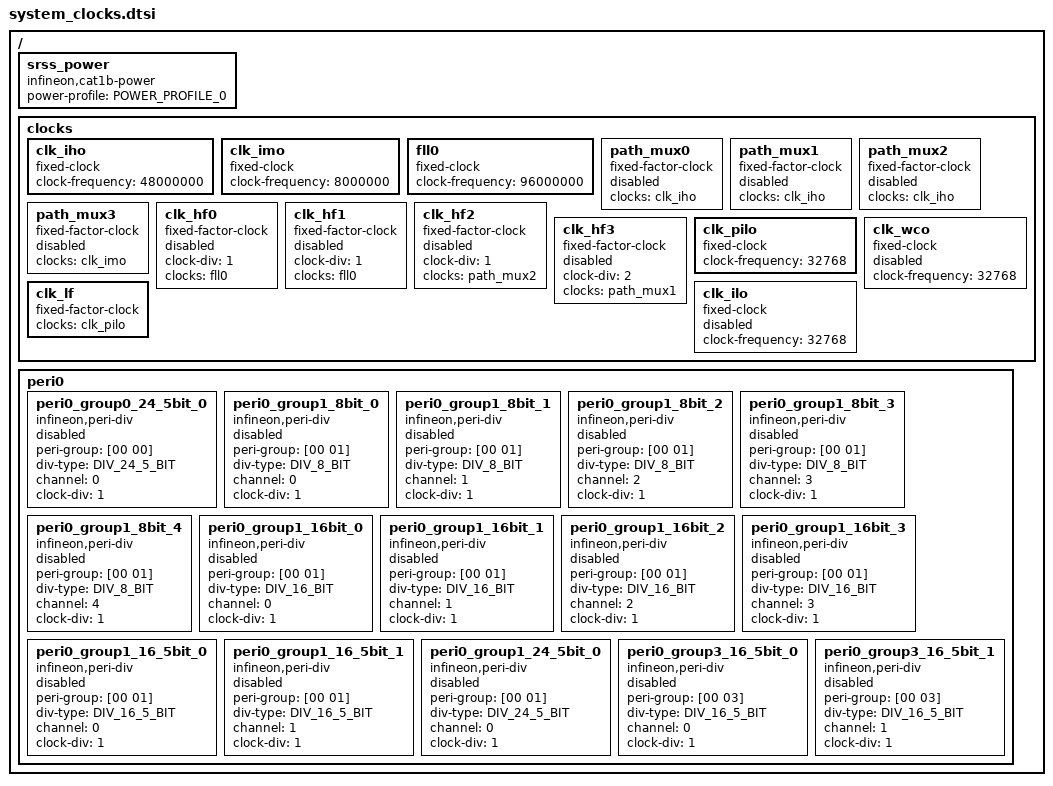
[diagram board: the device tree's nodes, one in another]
/*
 * Copyright (c) 2024 Cypress Semiconductor Corporation (an Infineon company) or
 * an affiliate of Cypress Semiconductor Corporation
 *
 * SPDX-License-Identifier: Apache-2.0
 */

#define DIV_8_BIT    00
#define DIV_16_BIT	 01
#define DIV_16_5_BIT 02
#define DIV_24_5_BIT 03

#include <dt-bindings/clock/ifx_clock_source_common.h>

/ {
	srss_power: srss_power {
		#clock-cells = <0>;
		compatible = "infineon,cat1b-power";
		power-profile = "POWER_PROFILE_0";
		status = "okay";
	};

	clocks {
		/* iho */
		clk_iho: clk_iho {
			#clock-cells = <0>;
			compatible = "fixed-clock";
			clock-frequency = <48000000>;
			status = "okay";
		};

		/* imo */
		clk_imo: clk_imo {
			#clock-cells = <0>;
			compatible = "fixed-clock";
			clock-frequency = <8000000>;
			status = "okay";
		};

		/* fll */
		fll0: fll0 {
			#clock-cells = <0>;
			compatible = "fixed-clock";
			clock-frequency = <96000000>;
			status = "okay";
		};

		/* path mux0 */
		path_mux0: path_mux0 {
			#clock-cells = <0>;
			compatible = "fixed-factor-clock";
			clocks = <&clk_iho>;
			status = "disabled";
		};

		/* path mux1 */
		path_mux1: path_mux1 {
			#clock-cells = <0>;
			compatible = "fixed-factor-clock";
			clocks = <&clk_iho>;
			status = "disabled";
		};

		/* path mux2 */
		path_mux2: path_mux2 {
			#clock-cells = <0>;
			compatible = "fixed-factor-clock";
			clocks = <&clk_iho>;
			status = "disabled";
		};

		/* path mux3 */
		path_mux3: path_mux3 {
			#clock-cells = <0>;
			compatible = "fixed-factor-clock";
			clocks = <&clk_imo>;
			status = "disabled";
		};

		/* clk_hf0 */
		clk_hf0: clk_hf0 {
			#clock-cells = <0>;
			compatible = "fixed-factor-clock";
			clock-div = <1>;
			clocks = <&fll0>;
			status = "disabled";
		};

		/* clk_hf1 */
		clk_hf1: clk_hf1 {
			#clock-cells = <0>;
			compatible = "fixed-factor-clock";
			clock-div = <1>;
			clocks = <&fll0>;
			status = "disabled";
		};

		/* clk_hf2 */
		clk_hf2: clk_hf2 {
			#clock-cells = <0>;
			compatible = "fixed-factor-clock";
			clock-div = <1>;
			clocks = <&path_mux2>;
			status = "disabled";
		};

		/* clk_hf3 */
		clk_hf3: clk_hf3 {
			#clock-cells = <0>;
			compatible = "fixed-factor-clock";
			clock-div = <2>;
			clocks = <&path_mux1>;
			status = "disabled";
		};

		/* LF frequency */

		/* pilo */
		clk_pilo: clk_pilo {
			#clock-cells = <0>;
			compatible = "fixed-clock";
			clock-frequency = <32768>;
			status = "okay";
		};

		/* wco */
		clk_wco: clk_wco {
			#clock-cells = <0>;
			compatible = "fixed-clock";
			clock-frequency = <32768>;
			status = "disabled";
		};

		/* ilo */
		clk_ilo: clk_ilo {
			#clock-cells = <0>;
			compatible = "fixed-clock";
			clock-frequency = <32768>;
			status = "disabled";
		};

		/* clk_lf */
		clk_lf: clk_lf {
			#clock-cells = <0>;
			compatible = "fixed-factor-clock";
			clocks = <&clk_pilo>;
			status = "okay";
		};
	};

	peri0: peri0 {
		/* Peripheral 0, Clock Group 0 */
		/* 24.5-bit */
		peri0_group0_24_5bit_0: peri0_group0_24_5bit_0 {
			#clock-cells = <0>;
			compatible = "infineon,peri-div";
			peri-group = [00 00]; /* inst#, group# */
			div-type = <DIV_24_5_BIT>;
			channel = <0>;
			clock-div = <1>;
			status = "disabled";
		};

		/* Peripheral 0, Clock Group 1 */
		/* 8-bit */
		peri0_group1_8bit_0: peri0_group1_8bit_0 {
			#clock-cells = <0>;
			compatible = "infineon,peri-div";
			peri-group = [00 01]; /* inst#, group# */
			div-type = <DIV_8_BIT>;
			channel = <0>;
			clock-div = <1>;
			status = "disabled";
		};

		peri0_group1_8bit_1: peri0_group1_8bit_1 {
			#clock-cells = <0>;
			compatible = "infineon,peri-div";
			peri-group = [00 01]; /* inst#, group# */
			div-type = <DIV_8_BIT>;
			channel = <1>;
			clock-div = <1>;
			status = "disabled";
		};

		peri0_group1_8bit_2: peri0_group1_8bit_2 {
			#clock-cells = <0>;
			compatible = "infineon,peri-div";
			peri-group = [00 01]; /* inst#, group# */
			div-type = <DIV_8_BIT>;
			channel = <2>;
			clock-div = <1>;
			status = "disabled";
		};

		peri0_group1_8bit_3: peri0_group1_8bit_3 {
			#clock-cells = <0>;
			compatible = "infineon,peri-div";
			peri-group = [00 01]; /* inst#, group# */
			div-type = <DIV_8_BIT>;
			channel = <3>;
			clock-div = <1>;
			status = "disabled";
		};

		peri0_group1_8bit_4: peri0_group1_8bit_4 {
			#clock-cells = <0>;
			compatible = "infineon,peri-div";
			peri-group = [00 01]; /* inst#, group# */
			div-type = <DIV_8_BIT>;
			channel = <4>;
			clock-div = <1>;
			status = "disabled";
		};

		/* 16-bit */
		peri0_group1_16bit_0: peri0_group1_16bit_0 {
			#clock-cells = <0>;
			compatible = "infineon,peri-div";
			peri-group = [00 01]; /* inst#, group# */
			div-type = <DIV_16_BIT>;
			channel = <0>;
			clock-div = <1>;
			status = "disabled";
		};

		peri0_group1_16bit_1: peri0_group1_16bit_1 {
			#clock-cells = <0>;
			compatible = "infineon,peri-div";
			peri-group = [00 01]; /* inst#, group# */
			div-type = <DIV_16_BIT>;
			channel = <1>;
			clock-div = <1>;
			status = "disabled";
		};

		peri0_group1_16bit_2: peri0_group1_16bit_2 {
			#clock-cells = <0>;
			compatible = "infineon,peri-div";
			peri-group = [00 01]; /* inst#, group# */
			div-type = <DIV_16_BIT>;
			channel = <2>;
			clock-div = <1>;
			status = "disabled";
		};

		peri0_group1_16bit_3: peri0_group1_16bit_3 {
			#clock-cells = <0>;
			compatible = "infineon,peri-div";
			peri-group = [00 01]; /* inst#, group# */
			div-type = <DIV_16_BIT>;
			channel = <3>;
			clock-div = <1>;
			status = "disabled";
		};

		/* 16.5-bit */
		peri0_group1_16_5bit_0: peri0_group1_16_5bit_0 {
			#clock-cells = <0>;
			compatible = "infineon,peri-div";
			peri-group = [00 01]; /* inst#, group# */
			div-type = <DIV_16_5_BIT>;
			channel = <0>;
			clock-div = <1>;
			status = "disabled";
		};

		peri0_group1_16_5bit_1: peri0_group1_16_5bit_1 {
			#clock-cells = <0>;
			compatible = "infineon,peri-div";
			peri-group = [00 01]; /* inst#, group# */
			div-type = <DIV_16_5_BIT>;
			channel = <1>;
			clock-div = <1>;
			status = "disabled";
		};

		/* 24.5-bit */
		peri0_group1_24_5bit_0: peri0_group1_24_5bit_0 {
			#clock-cells = <0>;
			compatible = "infineon,peri-div";
			peri-group = [00 01]; /* inst#, group# */
			div-type = <DIV_24_5_BIT>;
			channel = <0>;
			clock-div = <1>;
			status = "disabled";
		};

		/* Peripheral 0, Clock Group 3 */
		/* 16.5-bit */
		peri0_group3_16_5bit_0: peri0_group3_16_5bit_0 {
			#clock-cells = <0>;
			compatible = "infineon,peri-div";
			peri-group = [00 03]; /* inst#, group# */
			div-type = <DIV_16_5_BIT>;
			channel = <0>;
			clock-div = <1>;
			status = "disabled";
		};

		peri0_group3_16_5bit_1: peri0_group3_16_5bit_1 {
			#clock-cells = <0>;
			compatible = "infineon,peri-div";
			peri-group = [00 03]; /* inst#, group# */
			div-type = <DIV_16_5_BIT>;
			channel = <1>;
			clock-div = <1>;
			status = "disabled";
		};
	};
};
